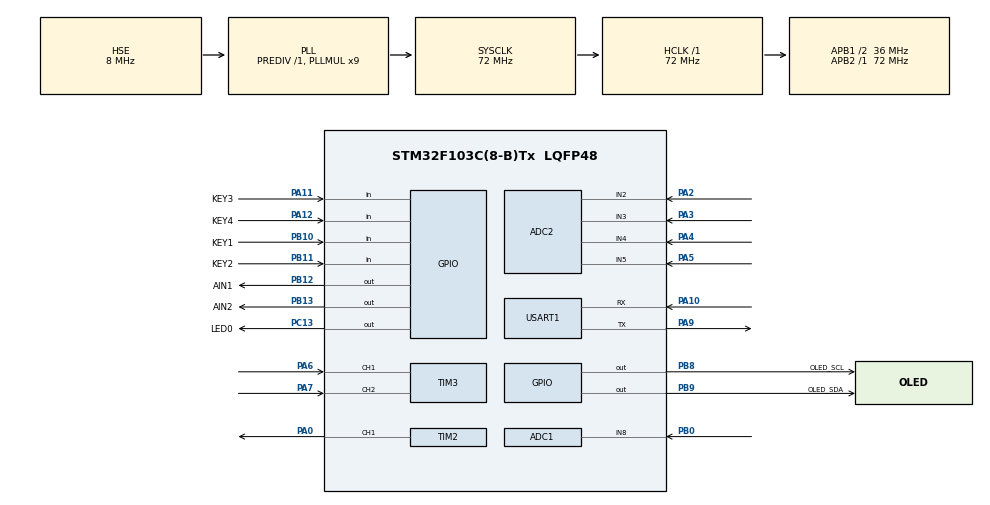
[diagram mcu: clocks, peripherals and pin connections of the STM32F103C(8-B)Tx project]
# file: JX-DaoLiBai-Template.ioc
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ADC1.Channel-0\#ChannelRegularConversion=ADC_CHANNEL_8
ADC1.NbrOfConversionFlag=1
ADC1.Rank-0\#ChannelRegularConversion=1
ADC1.SamplingTime-0\#ChannelRegularConversion=ADC_SAMPLETIME_1CYCLE_5
ADC1.master=1
ADC2.Channel-1\#ChannelRegularConversion=ADC_CHANNEL_2
ADC2.NbrOfConversionFlag=1
ADC2.Rank-1\#ChannelRegularConversion=1
ADC2.SamplingTime-1\#ChannelRegularConversion=ADC_SAMPLETIME_1CYCLE_5
Dma.Request0=USART1_RX
Dma.Request1=USART1_TX
Dma.USART1_RX.0.Direction=DMA_PERIPH_TO_MEMORY
Dma.USART1_RX.0.Instance=DMA1_Channel5
Dma.USART1_RX.0.MemDataAlignment=DMA_MDATAALIGN_BYTE
Dma.USART1_RX.0.MemInc=DMA_MINC_ENABLE
Dma.USART1_RX.0.Mode=DMA_NORMAL
Dma.USART1_RX.0.PeriphDataAlignment=DMA_PDATAALIGN_BYTE
Dma.USART1_RX.0.PeriphInc=DMA_PINC_DISABLE
Dma.USART1_RX.0.Priority=DMA_PRIORITY_LOW
Dma.USART1_TX.1.Direction=DMA_MEMORY_TO_PERIPH
Dma.USART1_TX.1.Instance=DMA1_Channel4
Dma.USART1_TX.1.MemDataAlignment=DMA_MDATAALIGN_BYTE
Dma.USART1_TX.1.MemInc=DMA_MINC_ENABLE
Dma.USART1_TX.1.Mode=DMA_NORMAL
Dma.USART1_TX.1.PeriphDataAlignment=DMA_PDATAALIGN_BYTE
Dma.USART1_TX.1.PeriphInc=DMA_PINC_DISABLE
Dma.USART1_TX.1.Priority=DMA_PRIORITY_LOW
Mcu.Family=STM32F1
Mcu.Name=STM32F103C(8-B)Tx
Mcu.Package=LQFP48
NVIC.DMA1_Channel4_IRQn=true\:0\:0\:false\:false\:true\:false\:true\:true
NVIC.DMA1_Channel5_IRQn=true\:0\:0\:false\:false\:true\:false\:true\:true
NVIC.PriorityGroup=NVIC_PRIORITYGROUP_2
NVIC.USART1_IRQn=true\:0\:0\:false\:false\:true\:true\:true\:true
PA0-WKUP.Signal=S_TIM2_CH1_ETR
PA10.Mode=Asynchronous
PA10.Signal=USART1_RX
PA11.GPIO_Label=KEY3
PA11.GPIO_Mode=GPIO_MODE_INPUT
PA11.GPIO_PuPd=GPIO_PULLUP
PA11.Signal=GPIO_Input
PA12.GPIO_Label=KEY4
PA12.GPIO_Mode=GPIO_MODE_INPUT
PA12.GPIO_PuPd=GPIO_PULLUP
PA12.Signal=GPIO_Input
PA13.Mode=Serial_Wire
PA13.Signal=SYS_JTMS-SWDIO
PA14.Mode=Serial_Wire
PA14.Signal=SYS_JTCK-SWCLK
PA2.Signal=ADCx_IN2
PA3.Signal=ADCx_IN3
PA4.Signal=ADCx_IN4
PA5.Signal=ADCx_IN5
PA6.Signal=S_TIM3_CH1
PA7.Signal=S_TIM3_CH2
PA9.Mode=Asynchronous
PA9.Signal=USART1_TX
PB0.Signal=ADCx_IN8
PB10.GPIO_Label=KEY1
PB10.GPIO_Mode=GPIO_MODE_INPUT
PB10.GPIO_PuPd=GPIO_PULLUP
PB10.Signal=GPIO_Input
PB11.GPIO_Label=KEY2
PB11.GPIO_Mode=GPIO_MODE_INPUT
PB11.GPIO_PuPd=GPIO_PULLUP
PB11.Signal=GPIO_Input
PB12.GPIO_Label=AIN1
PB12.Signal=GPIO_Output
PB13.GPIO_Label=AIN2
PB13.Signal=GPIO_Output
PB8.GPIO_Label=OLED_SCL
PB8.GPIO_Speed=GPIO_SPEED_FREQ_HIGH
PB8.Signal=GPIO_Output
PB9.GPIO_Label=OLED_SDA
PB9.GPIO_Speed=GPIO_SPEED_FREQ_HIGH
PB9.Signal=GPIO_Output
PC13-TAMPER-RTC.GPIO_Label=LED0
PC13-TAMPER-RTC.Signal=GPIO_Output
PC14-OSC32_IN.Mode=LSE-External-Oscillator
PC14-OSC32_IN.Signal=RCC_OSC32_IN
PC15-OSC32_OUT.Mode=LSE-External-Oscillator
PC15-OSC32_OUT.Signal=RCC_OSC32_OUT
PD0-OSC_IN.Mode=HSE-External-Oscillator
PD0-OSC_IN.Signal=RCC_OSC_IN
PD1-OSC_OUT.Mode=HSE-External-Oscillator
PD1-OSC_OUT.Signal=RCC_OSC_OUT
ProjectManager.HeapSize=0x200
ProjectManager.StackSize=0x400
ProjectManager.TargetToolchain=MDK-ARM V5.32
RCC.ADCPresc=RCC_ADCPCLK2_DIV6
RCC.AHBFreq_Value=72000000
RCC.APB1CLKDivider=RCC_HCLK_DIV2
RCC.APB1Freq_Value=36000000
RCC.APB1TimFreq_Value=72000000
RCC.APB2Freq_Value=72000000
RCC.APB2TimFreq_Value=72000000
RCC.HCLKFreq_Value=72000000
RCC.PLLMUL=RCC_PLL_MUL9
RCC.PLLSourceVirtual=RCC_PLLSOURCE_HSE
RCC.SYSCLKFreq_VALUE=72000000
RCC.SYSCLKSource=RCC_SYSCLKSOURCE_PLLCLK
RCC.USBFreq_Value=72000000
SH.ADCx_IN2.0=ADC2_IN2,IN2
SH.ADCx_IN3.0=ADC2_IN3,IN3
SH.ADCx_IN4.0=ADC2_IN4,IN4
SH.ADCx_IN5.0=ADC2_IN5,IN5
SH.ADCx_IN8.0=ADC1_IN8,IN8
SH.S_TIM2_CH1_ETR.0=TIM2_CH1,PWM Generation1 CH1
SH.S_TIM3_CH1.0=TIM3_CH1,Encoder_Interface
SH.S_TIM3_CH2.0=TIM3_CH2,Encoder_Interface
TIM2.AutoReloadPreload=TIM_AUTORELOAD_PRELOAD_ENABLE
TIM2.Channel-PWM\ Generation1\ CH1=TIM_CHANNEL_1
TIM2.Period=100-1
TIM2.Prescaler=36-1
TIM3.EncoderMode=TIM_ENCODERMODE_TI12
USART1.VirtualMode=VM_ASYNC
VP_TIM2_VS_ClockSourceINT.Mode=Internal
board=custom

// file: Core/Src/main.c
/* USER CODE BEGIN Header */
/**
  ******************************************************************************
  * @file           : main.c
  * @brief          : Main program body
  ******************************************************************************
  * @attention
  *
  * Copyright (c) 2026 STMicroelectronics.
  * All rights reserved.
  *
  * This software is licensed under terms that can be found in the LICENSE file
  * in the root directory of this software component.
  * If no LICENSE file comes with this software, it is provided AS-IS.
  *
  ******************************************************************************
  */
/* USER CODE END Header */
#include "main.h"
#include "adc.h"
#include "dma.h"
#include "tim.h"
#include "usart.h"
#include "gpio.h"

void SystemClock_Config(void);

/* USER CODE BEGIN 0 */
#include "Mymain.h"
/* USER CODE END 0 */

int main(void)
{

  /* MCU Configuration--------------------------------------------------------*/

  /* Reset of all peripherals, Initializes the Flash interface and the Systick. */
  HAL_Init();

  /* USER CODE BEGIN Init */

	// ��ʱ�ر� SysTick �ж�,������ܵ���ĳЩ���ܻ�û�н��г�ʼ��������,����ָ��ָ���,����Խ�����
  __disable_irq();

  /* USER CODE END Init */

  /* Configure the system clock */
  SystemClock_Config();

  /* Initialize all configured peripherals */
  MX_GPIO_Init();
  MX_DMA_Init();
  MX_USART1_UART_Init();
  MX_ADC2_Init();
  MX_TIM2_Init();
  MX_TIM3_Init();
  MX_ADC1_Init();
  /* USER CODE BEGIN 2 */
	Mymain() ;
  /* USER CODE END 2 */

  /* Infinite loop */
  while (1)
  {

  }
}

void SystemClock_Config(void)
{
  RCC_OscInitTypeDef RCC_OscInitStruct = {0};
  RCC_ClkInitTypeDef RCC_ClkInitStruct = {0};
  RCC_PeriphCLKInitTypeDef PeriphClkInit = {0};

  /** Initializes the RCC Oscillators according to the specified parameters
  * in the RCC_OscInitTypeDef structure.
  */
  RCC_OscInitStruct.OscillatorType = RCC_OSCILLATORTYPE_HSE;
  RCC_OscInitStruct.HSEState = RCC_HSE_ON;
  RCC_OscInitStruct.HSEPredivValue = RCC_HSE_PREDIV_DIV1;
  RCC_OscInitStruct.HSIState = RCC_HSI_ON;
  RCC_OscInitStruct.PLL.PLLState = RCC_PLL_ON;
  RCC_OscInitStruct.PLL.PLLSource = RCC_PLLSOURCE_HSE;
  RCC_OscInitStruct.PLL.PLLMUL = RCC_PLL_MUL9;
  if (HAL_RCC_OscConfig(&RCC_OscInitStruct) != HAL_OK)
  {
    Error_Handler();
  }

  /** Initializes the CPU, AHB and APB buses clocks
  */
  RCC_ClkInitStruct.ClockType = RCC_CLOCKTYPE_HCLK|RCC_CLOCKTYPE_SYSCLK
                              |RCC_CLOCKTYPE_PCLK1|RCC_CLOCKTYPE_PCLK2;
  RCC_ClkInitStruct.SYSCLKSource = RCC_SYSCLKSOURCE_PLLCLK;
  RCC_ClkInitStruct.AHBCLKDivider = RCC_SYSCLK_DIV1;
  RCC_ClkInitStruct.APB1CLKDivider = RCC_HCLK_DIV2;
  RCC_ClkInitStruct.APB2CLKDivider = RCC_HCLK_DIV1;

  if (HAL_RCC_ClockConfig(&RCC_ClkInitStruct, FLASH_LATENCY_2) != HAL_OK)
  {
    Error_Handler();
  }
  PeriphClkInit.PeriphClockSelection = RCC_PERIPHCLK_ADC;
  PeriphClkInit.AdcClockSelection = RCC_ADCPCLK2_DIV6;
  if (HAL_RCCEx_PeriphCLKConfig(&PeriphClkInit) != HAL_OK)
  {
    Error_Handler();
  }
}

void Error_Handler(void)
{
  __disable_irq();
  while (1)
  {
  }
}
